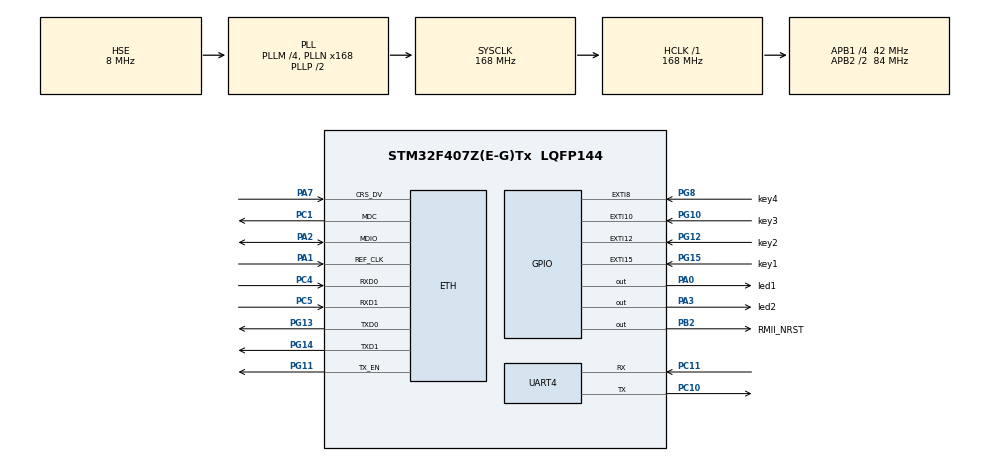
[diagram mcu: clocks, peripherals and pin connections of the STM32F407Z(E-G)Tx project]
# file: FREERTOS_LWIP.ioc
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ETH.MediaInterface=ETH_MEDIA_INTERFACE_RMII
ETH.PhyAddress=0
FREERTOS.Tasks01=defaultTask,24,1024,StartDefaultTask,Default,NULL,Dynamic,NULL,NULL;myTask02,8,1024,StartTask02,Default,NULL,Dynamic,NULL,NULL
FREERTOS.configTOTAL_HEAP_SIZE=30960
LWIP.GATEWAY_ADDRESS=192.168.001.001
LWIP.IP_ADDRESS=192.168.001.100
LWIP.LWIP_DHCP=0
LWIP.NETMASK_ADDRESS=255.255.255.000
LWIP.Version=v2.1.2_Cube
Mcu.Family=STM32F4
Mcu.Name=STM32F407Z(E-G)Tx
Mcu.Package=LQFP144
NVIC.ETH_IRQn=true\:5\:0\:false\:false\:true\:true\:true\:true
NVIC.EXTI15_10_IRQn=true\:5\:0\:false\:false\:true\:true\:true\:true
NVIC.EXTI9_5_IRQn=true\:5\:0\:false\:false\:true\:true\:true\:true
NVIC.PriorityGroup=NVIC_PRIORITYGROUP_4
NVIC.TIM1_UP_TIM10_IRQn=true\:15\:0\:false\:false\:true\:false\:false\:true
NVIC.TimeBase=TIM1_UP_TIM10_IRQn
NVIC.TimeBaseIP=TIM1
NVIC.UART4_IRQn=true\:5\:0\:false\:false\:true\:true\:true\:true
PA0-WKUP.GPIO_Label=led1
PA0-WKUP.GPIO_Speed=GPIO_SPEED_FREQ_HIGH
PA0-WKUP.PinState=GPIO_PIN_SET
PA0-WKUP.Signal=GPIO_Output
PA1.Mode=RMII
PA1.Signal=ETH_REF_CLK
PA13.Mode=JTAG_4_pins
PA13.Signal=SYS_JTMS-SWDIO
PA14.Mode=JTAG_4_pins
PA14.Signal=SYS_JTCK-SWCLK
PA15.Mode=JTAG_4_pins
PA15.Signal=SYS_JTDI
PA2.Mode=RMII
PA2.Signal=ETH_MDIO
PA3.GPIO_Label=led2
PA3.GPIO_Speed=GPIO_SPEED_FREQ_HIGH
PA3.PinState=GPIO_PIN_SET
PA3.Signal=GPIO_Output
PA7.Mode=RMII
PA7.Signal=ETH_CRS_DV
PB2.GPIO_Label=RMII_NRST
PB2.GPIO_PuPd=GPIO_PULLUP
PB2.PinState=GPIO_PIN_SET
PB2.Signal=GPIO_Output
PB3.Mode=JTAG_4_pins
PB3.Signal=SYS_JTDO-SWO
PC1.Mode=RMII
PC1.Signal=ETH_MDC
PC10.Mode=Asynchronous
PC10.Signal=UART4_TX
PC11.Mode=Asynchronous
PC11.Signal=UART4_RX
PC14-OSC32_IN.Mode=LSE-External-Oscillator
PC14-OSC32_IN.Signal=RCC_OSC32_IN
PC15-OSC32_OUT.Mode=LSE-External-Oscillator
PC15-OSC32_OUT.Signal=RCC_OSC32_OUT
PC4.Mode=RMII
PC4.Signal=ETH_RXD0
PC5.Mode=RMII
PC5.Signal=ETH_RXD1
PG10.GPIO_Label=key3
PG10.GPIO_ModeDefaultEXTI=GPIO_MODE_IT_FALLING
PG10.GPIO_PuPd=GPIO_PULLUP
PG10.Signal=GPXTI10
PG11.Mode=RMII
PG11.Signal=ETH_TX_EN
PG12.GPIO_Label=key2
PG12.GPIO_ModeDefaultEXTI=GPIO_MODE_IT_FALLING
PG12.GPIO_PuPd=GPIO_PULLUP
PG12.Signal=GPXTI12
PG13.Mode=RMII
PG13.Signal=ETH_TXD0
PG14.Mode=RMII
PG14.Signal=ETH_TXD1
PG15.GPIO_Label=key1
PG15.GPIO_ModeDefaultEXTI=GPIO_MODE_IT_FALLING
PG15.GPIO_PuPd=GPIO_PULLUP
PG15.Signal=GPXTI15
PG8.GPIO_Label=key4
PG8.GPIO_ModeDefaultEXTI=GPIO_MODE_IT_FALLING
PG8.GPIO_PuPd=GPIO_PULLUP
PG8.Signal=GPXTI8
PH0-OSC_IN.Mode=HSE-External-Oscillator
PH0-OSC_IN.Signal=RCC_OSC_IN
PH1-OSC_OUT.Mode=HSE-External-Oscillator
PH1-OSC_OUT.Signal=RCC_OSC_OUT
ProjectManager.HeapSize=0X400
ProjectManager.StackSize=0x800
ProjectManager.TargetToolchain=MDK-ARM V5.32
RCC.48MHZClocksFreq_Value=84000000
RCC.AHBFreq_Value=168000000
RCC.APB1CLKDivider=RCC_HCLK_DIV4
RCC.APB1Freq_Value=42000000
RCC.APB1TimFreq_Value=84000000
RCC.APB2CLKDivider=RCC_HCLK_DIV2
RCC.APB2Freq_Value=84000000
RCC.APB2TimFreq_Value=168000000
RCC.CortexFreq_Value=168000000
RCC.HCLKFreq_Value=168000000
RCC.HSE_VALUE=8000000
RCC.HSI_VALUE=16000000
RCC.PLLM=4
RCC.PLLN=168
RCC.PLLSourceVirtual=RCC_PLLSOURCE_HSE
RCC.SYSCLKFreq_VALUE=168000000
RCC.SYSCLKSource=RCC_SYSCLKSOURCE_PLLCLK
RCC.VCOOutputFreq_Value=336000000
UART4.VirtualMode=Asynchronous
VP_FREERTOS_VS_CMSIS_V2.Mode=CMSIS_V2
VP_LWIP_VS_Enabled.Mode=Enabled
VP_SYS_VS_tim1.Mode=TIM1
board=custom

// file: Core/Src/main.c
/* USER CODE BEGIN Header */
/**
  ******************************************************************************
  * @file           : main.c
  * @brief          : Main program body
  ******************************************************************************
  * @attention
  *
  * Copyright (c) 2025 STMicroelectronics.
  * All rights reserved.
  *
  * This software is licensed under terms that can be found in the LICENSE file
  * in the root directory of this software component.
  * If no LICENSE file comes with this software, it is provided AS-IS.
  *
  ******************************************************************************
  */
/* USER CODE END Header */
/* USER CODE BEGIN Includes */
#include "includes.h"
/* USER CODE END Includes */

void SystemClock_Config(void);
void MX_FREERTOS_Init(void);

int main(void)
{

  /* MCU Configuration--------------------------------------------------------*/

  /* Reset of all peripherals, Initializes the Flash interface and the Systick. */
  HAL_Init();

  /* Configure the system clock */
  SystemClock_Config();

  /* Initialize all configured peripherals */
  MX_GPIO_Init();
  MX_UART4_Init();

  /* Init scheduler */
	key_fifoinit(&s_tKey);
  osKernelInitialize();  /* Call init function for freertos objects (in freertos.c) */
  AppTaskCreate();
	AppObjCreate();
  /* Start scheduler */
  osKernelStart();

  /* We should never get here as control is now taken by the scheduler */
  /* Infinite loop */
  while (1)
  {

  }
}

void SystemClock_Config(void)
{
  RCC_OscInitTypeDef RCC_OscInitStruct = {0};
  RCC_ClkInitTypeDef RCC_ClkInitStruct = {0};

  /** Configure the main internal regulator output voltage
  */
  __HAL_RCC_PWR_CLK_ENABLE();
  __HAL_PWR_VOLTAGESCALING_CONFIG(PWR_REGULATOR_VOLTAGE_SCALE1);
  /** Initializes the RCC Oscillators according to the specified parameters
  * in the RCC_OscInitTypeDef structure.
  */
  RCC_OscInitStruct.OscillatorType = RCC_OSCILLATORTYPE_HSE;
  RCC_OscInitStruct.HSEState = RCC_HSE_ON;
  RCC_OscInitStruct.PLL.PLLState = RCC_PLL_ON;
  RCC_OscInitStruct.PLL.PLLSource = RCC_PLLSOURCE_HSE;
  RCC_OscInitStruct.PLL.PLLM = 4;
  RCC_OscInitStruct.PLL.PLLN = 168;
  RCC_OscInitStruct.PLL.PLLP = RCC_PLLP_DIV2;
  RCC_OscInitStruct.PLL.PLLQ = 4;
  if (HAL_RCC_OscConfig(&RCC_OscInitStruct) != HAL_OK)
  {
    Error_Handler();
  }
  /** Initializes the CPU, AHB and APB buses clocks
  */
  RCC_ClkInitStruct.ClockType = RCC_CLOCKTYPE_HCLK|RCC_CLOCKTYPE_SYSCLK
                              |RCC_CLOCKTYPE_PCLK1|RCC_CLOCKTYPE_PCLK2;
  RCC_ClkInitStruct.SYSCLKSource = RCC_SYSCLKSOURCE_PLLCLK;
  RCC_ClkInitStruct.AHBCLKDivider = RCC_SYSCLK_DIV1;
  RCC_ClkInitStruct.APB1CLKDivider = RCC_HCLK_DIV4;
  RCC_ClkInitStruct.APB2CLKDivider = RCC_HCLK_DIV2;

  if (HAL_RCC_ClockConfig(&RCC_ClkInitStruct, FLASH_LATENCY_5) != HAL_OK)
  {
    Error_Handler();
  }
}

void HAL_TIM_PeriodElapsedCallback(TIM_HandleTypeDef *htim)
{
  if (htim->Instance == TIM1) {
    HAL_IncTick();
  }
}

void Error_Handler(void)
{
  __disable_irq();
  while (1)
  {
  }
}

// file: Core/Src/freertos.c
/* USER CODE BEGIN Header */
/**
  ******************************************************************************
  * File Name          : freertos.c
  * Description        : Code for freertos applications
  ******************************************************************************
  * @attention
  *
  * Copyright (c) 2025 STMicroelectronics.
  * All rights reserved.
  *
  * This software is licensed under terms that can be found in the LICENSE file
  * in the root directory of this software component.
  * If no LICENSE file comes with this software, it is provided AS-IS.
  *
  ******************************************************************************
  */
/* USER CODE END Header */

/* USER CODE BEGIN Includes */
#include "includes.h"
/* USER CODE END Includes */

/* Definitions for defaultTask */
osThreadId_t defaultTaskHandle;
const osThreadAttr_t defaultTask_attributes = {
  .name = "defaultTask",
  .stack_size = 1024 * 4,
  .priority = (osPriority_t) osPriorityNormal,
};
/* Definitions for myTask02 */
osThreadId_t myTask02Handle;
const osThreadAttr_t myTask02_attributes = {
  .name = "myTask02",
  .stack_size = 1024 * 4,
  .priority = (osPriority_t) osPriorityLow,
};

void StartDefaultTask(void *argument);
void StartTask02(void *argument);

extern void MX_LWIP_Init(void);
void MX_FREERTOS_Init(void); /* (MISRA C 2004 rule 8.1) */

void MX_FREERTOS_Init(void) {

  /* Create the thread(s) */
  /* creation of defaultTask */
  defaultTaskHandle = osThreadNew(StartDefaultTask, NULL, &defaultTask_attributes);

  /* creation of myTask02 */
  myTask02Handle = osThreadNew(StartTask02, NULL, &myTask02_attributes);

}

void StartDefaultTask(void *argument)
{
  /* init code for LWIP */
  MX_LWIP_Init();
  /* USER CODE BEGIN StartDefaultTask */
	printf("123");
  /* Infinite loop */
  for(;;)
  {
    osDelay(1);
  }
  /* USER CODE END StartDefaultTask */
}

void StartTask02(void *argument)
{
  /* USER CODE BEGIN StartTask02 */
  /* Infinite loop */
  for(;;)
  {
		vTCPServer_Task();
    osDelay(1);
  }
  /* USER CODE END StartTask02 */
}
